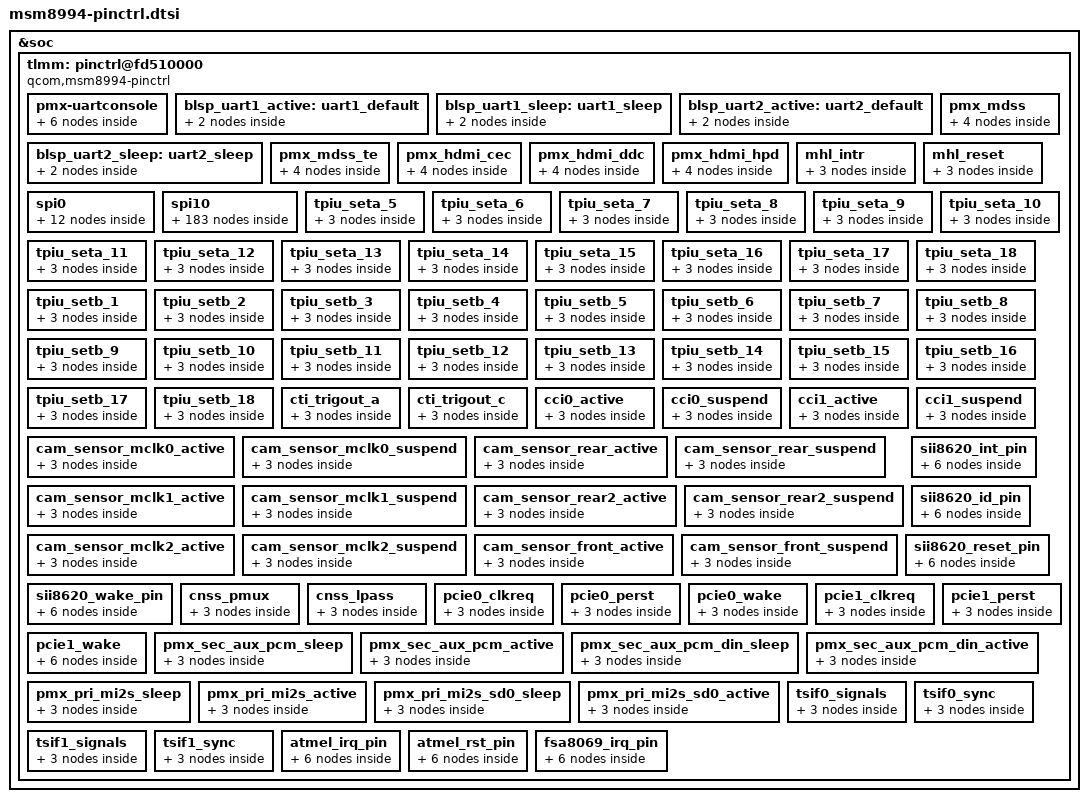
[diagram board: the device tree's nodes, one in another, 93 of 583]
/* Copyright (c) 2013-2015, The Linux Foundation. All rights reserved.
 *
 * This program is free software; you can redistribute it and/or modify
 * it under the terms of the GNU General Public License version 2 and
 * only version 2 as published by the Free Software Foundation.
 *
 * This program is distributed in the hope that it will be useful,
 * but WITHOUT ANY WARRANTY; without even the implied warranty of
 * MERCHANTABILITY or FITNESS FOR A PARTICULAR PURPOSE.  See the
 * GNU General Public License for more details.
 */

&soc {
	tlmm: pinctrl@fd510000 {
		compatible = "qcom,msm8994-pinctrl";
		reg = <0xfd510000 0x4000>;
		interrupts = <0 208 0>;
		gpio-controller;
		#gpio-cells = <2>;
		interrupt-controller;
		#interrupt-cells = <2>;

		pmx-uartconsole {
			uart_console_active: uart_console_active {
				mux {
					pins = "gpio4", "gpio5";
					function = "blsp_uart2";
				};

				config {
					pins = "gpio4", "gpio5";
					drive-strength = <2>;
					bias-disable;
				};
			};

			uart_console_sleep: uart_console_sleep {
				mux {
					pins = "gpio4", "gpio5";
					function = "blsp_uart2";
				};

				config {
					pins = "gpio4", "gpio5";
					drive-strength = <2>;
					bias-pull-down;
				};
			};
		};

		// add by ztemt start
		// add the uart pinctrl for IR-remote control
		blsp_uart1_active: uart1_default {
			mux {
				pins = "gpio0", "gpio1", "gpio2", "gpio3";
				function = "blsp_uart1";
			};

			config {
				pins = "gpio0", "gpio1", "gpio2", "gpio3";
				drive-strength = <16>;
				bias-disable;
			};
		};

		blsp_uart1_sleep: uart1_sleep {
			mux {
				pins = "gpio0", "gpio1";
				function = "gpio";
			};

			config {
				pins = "gpio0", "gpio1";
				drive-strength = <2>;
				bias-pull-down;
				output-low;
			};
		};
		// add by ztemt end

		blsp_uart2_active: uart2_default {
			mux {
				pins = "gpio45", "gpio46", "gpio47", "gpio48";
				function = "blsp_uart8";
			};

			config {
				pins = "gpio45", "gpio46", "gpio47", "gpio48";
				drive-strength = <16>;
				bias-disable;
			};
		};

		blsp_uart2_sleep: uart2_sleep {
			mux {
				pins = "gpio45", "gpio46", "gpio47", "gpio48";
				function = "gpio";
			};

			config {
				pins = "gpio45", "gpio46", "gpio47", "gpio48";
				drive-strength = <2>;
				bias-disable;
			};
		};

		pmx_mdss: pmx_mdss {
			// label = "mdss-pins";
			// qcom,pin-func = <0>;
			mdss_dsi_active: active {
				config {
					drive-strength = <8>; /* 8 mA */
					bias-disable = <0>; /* no pull */
				};
			};
			mdss_dsi_suspend: suspend {
				config {
					drive-strength = <2>; /* 2 mA */
					bias-pull-down; /* pull down */
				};
			};
		};

		pmx_mdss_te: pmx_mdss_te {
			// label = "mdss-te-pins";
			// qcom,pin-func = <1>;
			mdss_te_active: active {
				config {
					drive-strength = <2>; /* 8 mA */
					bias-pull-down = <0>; /* pull down*/
					input-debounce = <0>;
				};
			};
			mdss_te_suspend: suspend {
				config {
					drive-strength = <2>; /* 2 mA */
					bias-pull-down; /* pull down */
					input-debounce = <0>;
				};
			};
		};

		pmx_hdmi_cec: pmx_hdmi_cec {
			// qcom,pin-func = <1>;
			// label = "hdmi-cec-pins";
			mdss_hdmi_cec_active: cec_active {
				config {
					drive-strength = <2>;
					bias-pull-up;
				};
			};
			mdss_hdmi_cec_suspend: cec_suspend {
				config {
					drive-strength = <2>;
					bias-pull-down;
				};
			};
		};

		pmx_hdmi_ddc: pmx_hdmi_ddc {
			// qcom,pin-func = <1>;
			// label = "hdmi-ddc-pins";
			mdss_hdmi_ddc_active: ddc_active {
				config {
					drive-strength = <2>;
					bias-pull-up;
				};
			};
			mdss_hdmi_ddc_suspend: ddc_suspend {
				config {
					drive-strength = <2>;
					bias-disable;
				};
			};
		};

		pmx_hdmi_hpd: pmx_hdmi_hpd {
			// qcom,pin-func = <1>;
			// label = "hdmi-hpd-pin";
			mdss_hdmi_hpd_active: hpd_active {
				config {
					drive-strength = <16>;
					bias-pull-down;
				};
			};
			mdss_hdmi_hpd_suspend: hpd_suspend {
				config {
					drive-strength = <2>;
					bias-pull-down;
				};
			};
		};

		mhl_intr: mhl_intr {
			// qcom,pins = <&gp 57>;
			// qcom,num-grp-pins = <1>;
			// qcom,pin-func = <0>;
			// label = "mhl_intr";

			mhl_intr_active: mhl_intr_active {
				mux {
					pins = "gpio57";
					function = "gpio";
				};

				config {
					pins = "gpio57";
					bias-pull-up;
					input-enable;
				};
			};
		};

		mhl_reset: mhl_reset {
			// qcom,pins = <&gp 58>;
			// qcom,num-grp-pins = <1>;
			// qcom,pin-func = <0>;
			// label = "mhl_reset";

			mhl_reset_active: mhl_reset_active {
				mux {
					pins = "gpio58";
					function = "gpio";
				};

				config {
					pins = "gpio58";
					drive-strength = <2>;
					bias-pull-down;
					output-low;
				};
			};
		};

		spi0 {

			spi_0_active: spi0_active {
				/* active state */
				mux {
					/* MOSI, MISO, CLK */
					pins = "gpio0", "gpio1", "gpio3";
					function = "blsp_spi1";
				};

				config {
					pins = "gpio0", "gpio1", "gpio3";
					drive-strength = <12>; /* 12 MA */
					bias-disable = <0>; /* No PULL */
				};
			};


			spi_0_sleep: spi0_sleep {
				/* suspended state */
				mux {
					/* MOSI, MISO, CLK */
					pins = "gpio0", "gpio1", "gpio3";
					function = "blsp_spi1";
				};

				config {
					pins = "gpio0", "gpio1", "gpio3";
					drive-strength = <2>; /* 2 MA */
					bias-pull-down; /* PULL Down */
				};
			};

			spi_0_cs1_active: cs1_active {
				/* CS */
				mux {
					pins = "gpio8";
					function = "blsp_spi1";
				};

				config {
					pins = "gpio8";
					drive-strength = <2>;
					bias-disable = <0>;
				};
			};

			spi_0_cs1_sleep: cs1_sleep {
				/* CS */
				mux {
					pins = "gpio8";
					function = "blsp_spi1";
				};

				config {
					pins = "gpio8";
					drive-strength = <2>;
					bias-disable = <0>;
				};
			};
		};

		
	/* spi_10 */
		spi10 {
			spi_10_active: spi10_active {

				mux {
					/* MOSI, MISO */
					pins = "gpio53", "gpio54";
					function = "blsp_spi10";
				};

				config {
					pins = "gpio53", "gpio54";
					drive-strength = <2>; /* 2 MA */
					bias-disable = <0>;
				};
			};

			spi_10_sleep: spi10_sleep {
				mux {
					/* MOSI, MISO */
					pins = "gpio53", "gpio54";
					function = "blsp_spi10";
				};

				config {
					pins = "gpio53", "gpio54";
					drive-strength = <2>; /* 2 MA */
					bias-pull-down;
				};
			};

			spi_10_cs10_active: spi_cs10_active {
				/* CS10 , CLK */
				mux {
					/* MOSI, MISO */
					pins = "gpio55", "gpio56";
					function = "blsp_spi10";
				};

				config {
					pins = "gpio55", "gpio56";
					drive-strength = <2>; /* 2 MA */
					bias-disable = <0>;
				};
			};

			spi_10_cs10_sleep: spi_cs10_sleep {
				mux {
					/* MOSI, MISO */
					pins = "gpio55", "gpio56";
					function = "blsp_spi10";
				};

				config {
					pins = "gpio55", "gpio56";
					drive-strength = <2>; /* 2 MA */
					bias-disable = <0>;
				};

		};

	/* spi_12 */
		spi12 {
			spi_12_active: spi12_active {
				mux {
					/* MOSI, MISO */
					pins = "gpio85", "gpio86";
					function = "blsp_spi12";
				};

				config {
					pins = "gpio85", "gpio86";
					drive-strength = <2>; /* 2 MA */
					bias-disable = <0>;
				};
			};
			
			spi_12_sleep: spi12_sleep {
				mux {
					/* MOSI, MISO */
					pins = "gpio85", "gpio86";
					function = "blsp_spi12";
				};

				config {
					pins = "gpio85", "gpio86";
					drive-strength = <2>; /* 2 MA */
					bias-pull-down;
				};
			};

			spi_12_cs_active: cs12_active {
				/* CS12 , CLK */
				mux {
					pins = "gpio87", "gpio88";
					function = "blsp_spi12";
				};

				config {
					pins = "gpio87", "gpio88";
					drive-strength = <8>; /* 2 MA */
					bias-disable = <0>;
				};
			};

			spi_12_cs_sleep: cs12_sleep {
				mux {
					/* MOSI, MISO */
					pins = "gpio87", "gpio88";
					function = "blsp_spi12";
				};

				config {
					pins = "gpio87", "gpio88";
					drive-strength = <2>; /* 2 MA */
					bias-disable = <0>;
				};
			};
		};
		pmx_i2c_1 {
			i2c_1_active: i2c_1_active {
				mux {
					/* SDA, SCL */
					pins = "gpio2", "gpio3";
					function = "blsp_i2c1";
				};

				config {
					pins = "gpio2", "gpio3";
					drive-strength = <2>; /* 2 MA */
					bias-disable;
				};
			};

			i2c_1_sleep: i2c_1_sleep {
				mux {
					/* SDA, SCL */
					pins = "gpio2", "gpio3";
					function = "blsp_i2c1";
				};

				config {
					pins = "gpio2", "gpio3";
					drive-strength = <2>; /* 2 MA */
					bias-disable;
				};
			};
		};

		audio_ext_devices {
			/* default state */
			audio_ext_speakers: audio_ext_speakers {
				mux {
					pins = "gpio96";
					function = "gpio";
				};

				config {
					pins = "gpio96";
					drive-strength = <2>; /* 2 MA */
					bias-pull-up;
				};
			};
		};

		/* SDC pin type */
		sdc: sdc {
			/*
			 * 0-3 for sdc1
			 * 4-6 for sdc2
			 * 7-9 for sdc3
			 */
			qcom,num-pins = <10>;
			/*
			 * Order of pins:
			 * SDC1: CLK -> 0, CMD -> 1, DATA -> 2, RCLK -> 3
			 * SDC2: CLK -> 4, CMD -> 5, DATA -> 6
			 * SDC3: CLK -> 7, CMD -> 8, DATA -> 9
			 */
			#qcom,pin-cells = <1>;
		};

		pmx_sdc1_clk {
			sdc1_clk_on: clk_on {
				config {
					pins = "sdc1_clk";
					bias-disable;		/* NO pull */
					drive-strength = <16>;	/* 16 MA */
				};
			};
			sdc1_clk_off: clk_off {
				config {
					pins = "sdc1_clk";
					bias-disable;		/* NO pull */
					drive-strength = <2>;	/* 2 MA */
				};
			};
		};

		pmx_sdc1_cmd {
			sdc1_cmd_on: cmd_on {
				config {
					pins = "sdc1_cmd";
					bias-pull-up;		/* pull up */
					drive-strength = <8>;	/* 8 MA */
				};
			};
			sdc1_cmd_off: cmd_off {
				config {
					pins = "sdc1_cmd";
					num-grp-pins = <1>;
					bias-pull-up;		/* pull up */
					drive-strength = <2>;	/* 2 MA */
				};
			};
		};

		pmx_sdc1_data {
			sdc1_data_on: data_on {
				config {
					pins = "sdc1_data";
					bias-pull-up;		/* pull up */
					drive-strength = <8>;	/* 8 MA */
				};
			};
			sdc1_data_off: data_off {
				config {
					pins = "sdc1_data";
					bias-pull-up;		/* pull up */
					drive-strength = <2>;	/* 2 MA */
				};
			};
		};

		pmx_sdc1_rclk {
			sdc1_rclk_on: rclk_on {
				config {
					pins = "sdc1_rclk";
					bias-pull-down;		/* pull down */
				};
			};
			sdc1_rclk_off: rclk_off {
				config {
					pins = "sdc1_rclk";
					bias-pull-down;		/* pull down */
				};
			};
		};

		pmx_sdc2_clk {
			sdc2_clk_on: clk_on {
				config {
					pins = "sdc2_clk";
					bias-disable;		/* NO pull */
					drive-strength = <16>;	/* 16 MA */
				};
			};
			sdc2_clk_off: clk_off {
				config {
					pins = "sdc2_clk";
					bias-disable;		/* NO pull */
					drive-strength = <2>;	/* 2 MA */
				};
			};
		};

		pmx_sdc2_cmd {
			sdc2_cmd_on: cmd_on {
				config {
					pins = "sdc2_cmd";
					bias-pull-up;		/* pull up */
					drive-strength = <10>;	/* 10 MA */
				};
			};
			sdc2_cmd_off: cmd_off {
				config {
					pins = "sdc2_cmd";
					bias-pull-up;		/* pull up */
					drive-strength = <2>;	/* 2 MA */
				};
			};
		};

		pmx_sdc2_data {
			sdc2_data_on: data_on {
				config {
					pins = "sdc2_data";
					bias-pull-up;		/* pull up */
					drive-strength = <10>;	/* 10 MA */
				};
			};
			sdc2_data_off: data_off {
				config {
					pins = "sdc2_data";
					bias-pull-up;		/* pull up */
					drive-strength = <2>;	/* 2 MA */
				};
			};
		};

		pmx_sdc3_clk {
			sdc3_clk_on: clk_on {
				config {
					pins = "sdc3_clk";
					bias-disable;		/* NO pull */
					drive-strength = <16>;	/* 16 MA */
				};
			};
			sdc3_clk_off: clk_off {
				config {
					pins = "sdc3_clk";
					bias-disable;		/* NO pull */
					drive-strength = <2>;	/* 2 MA */
				};
			};
		};

		pmx_sdc3_cmd {
			sdc3_cmd_on: cmd_on {
				config {
					pins = "sdc3_cmd";
					bias-pull-up;		/* pull up */
					drive-strength = <10>;	/* 10 MA */
				};
			};
			sdc3_cmd_off: cmd_off {
				config {
					pins = "sdc3_cmd";
					bias-pull-up;		/* pull up */
					drive-strength = <2>;	/* 2 MA */
				};
			};
		};

		pmx_sdc3_data {
			sdc3_data_on: data_on {
				config {
					pins = "sdc3_data";
					bias-pull-up;		/* pull up */
					drive-strength = <10>;	/* 10 MA */
				};
			};
			sdc3_data_off: data_off {
				config {
					pins = "sdc3_data";
					bias-pull-up;		/* pull up */
					drive-strength = <2>;	/* 2 MA */
				};
			};
		};

		pmx_i2c_2 {
			/* active state */
			i2c_2_active: i2c_2_active{
				mux {
					/* CLK, DATA */
					pins = "gpio6", "gpio7";
					function = "blsp_i2c2";
				};

				config {
					pins = "gpio6", "gpio7";
					drive-strength = <2>; /* 2 MA */
					bias-disable; /* No PULL */
				};
			};

			/* suspended state */
			i2c_2_sleep: i2c_2_sleep {
				mux {
					/* CLK, DATA */
					pins = "gpio6", "gpio7";
					function = "blsp_i2c2";
				};

				config {
					pins = "gpio6", "gpio7";
					drive-strength = <2>; /* 2 MA */
					bias-disable; /* No PULL */
				};
			};
		};

		pmx_i2c_11 {
			/* active state */
			i2c_11_active: i2c_11_active{
				mux {
					/* CLK, DATA */
					pins = "gpio83", "gpio84";
					function = "blsp_i2c11";
				};

				config {
					pins = "gpio83", "gpio84";
					drive-strength = <2>; /* 2 MA */
					bias-disable; /* No PULL */
				};
			};

			/* suspended state */
			i2c_11_sleep: i2c_11_sleep {
				mux {
					/* CLK, DATA */
					pins = "gpio83", "gpio84";
					function = "blsp_i2c11";
				};

				config {
					pins = "gpio83", "gpio84";
					drive-strength = <2>; /* 2 MA */
					bias-disable; /* No PULL */
				};
			};
		};

		pmx_fm_int_active {
			// qcom,pins = <&gp 9>;
			// qcom,pin-func = <0>;
			// qcom,num-grp-pins = <1>;
			// label = "pmx_fm_int_active";

			fm_int_active: fm_int_active {
				mux {
					pins = "gpio9";
					function = "gpio";
				};

				config {
					pins = "gpio9";
					drive-strength = <16>;
					bias-pull-up;
				};
			};
		};

		pmx_fm_int_suspend {
			fm_int_suspend: fm_int_suspend {
				mux {
					pins = "gpio9";
					function = "gpio";
				};

				config {
					pins = "gpio9";
					drive-strength = <16>;
					bias-pull-up;
				};
			};
		};

		pmx_fm_status_int_active {
			fm_status_int_active: fm_status_int_active {
				mux {
					pins = "gpio11";
					function = "gpio";
				};

				config {
					pins = "gpio11";
					drive-strength = <16>;
					bias-pull-up;
				};
			};
		};

		pmx_fm_status_int_suspend {
			fm_status_int_suspend: fm_status_int_suspend {
				mux {
					pins = "gpio11";
					function = "gpio";
				};

				config {
					pins = "gpio11";
					drive-strength = <16>;
					bias-pull-up;
				};
			};
		};

		pmx_fm_rst_active {
			fm_rst_active: fm_rst_active {
				mux {
					pins = "gpio62";
					function = "gpio";
				};

				config {
					pins = "gpio62";
					drive-strength = <16>;
					bias-pull-down;
				};
			};
		};

		pmx_fm_rst_suspend {
			fm_rst_suspend: fm_rst_suspend {
				mux {
					pins = "gpio62";
					function = "gpio";
				};

				config {
					pins = "gpio62";
					drive-strength = <16>;
					bias-pull-down;
				};
			};
		};

		pmx_i2c_6 {
			/* active state */
			i2c_6_active: i2c_6_active{
				mux {
					/* SDA, SCL */
					pins = "gpio28", "gpio27";
					function = "blsp_i2c6";
				};

				config {
					pins = "gpio28", "gpio27";
					drive-strength = <2>; /* 2 MA */
					bias-disable; /* No PULL */
				};
			};

			/* suspended state */
			i2c_6_sleep: i2c_6_sleep {
				mux {
					/* CLK, DATA */
					pins = "gpio28", "gpio27";
					function = "blsp_i2c6";
				};

				config {
					pins = "gpio28", "gpio27";
					drive-strength = <2>; /* 2 MA */
					bias-disable; /* No PULL */
				};
			};
		};

		// add by ztemt start
		// add the senor pinctrl
		als_prox_int{
			// qcom,pins = <&gp 40>;
			// qcom,pin-func = <0>;
			// qcom,num-grp-pins = <1>;
			// label = "als_prox_int";

			als_prox_int_active: active {
				mux {
					pins = "gpio40";
					function = "gpio";
				};

				config {
					pins = "gpio40";
					drive-strength = <12>;
					bias-pull-up;
				};
			};

			als_prox_int_suspend: suspend {
				mux {
					pins = "gpio40";
					function = "gpio";
				};

				config {
					pins = "gpio40";
					drive-strength = <6>;
					bias-pull-up;
				};
			};
		};
		// add by ztemt end
/*
		pmx_rd_nfc_int{
			qcom,pins = <&gp 29>;
			qcom,pin-func = <0>;
			qcom,num-grp-pins = <1>;
			label = "pmx_nfc_int";

			nfc_int_active: active {
				drive-strength = <6>;
				bias-pull-up;
			};

			nfc_int_suspend: suspend {
				drive-strength = <6>;
				bias-pull-up;
			};
		};

		pmx_nfc_reset{
			qcom,pins = <&gp 30>;
			qcom,pin-func = <0>;
			qcom,num-grp-pins = <1>;
			label = "pmx_nfc_disable";

			nfc_disable_active: active {
				drive-strength = <6>;
				bias-pull-up;
			};

			nfc_disable_suspend: suspend {
				drive-strength = <6>;
				bias-disable;
			};
		};
*/
		/*add by chengdongsheng for nfc brcm2079x*/
		bcm2079x_int_pin{
			bcm2079x_int_active: active {
				mux {
					pins = "gpio29";
					function = "gpio";
				};

				config {
					pins = "gpio29";
					drive-strength = <6>;
					bias-pull-up;
				};
			};
			
			bcm2079x_int_suspend: suspend {
				mux {
					pins = "gpio29";
					function = "gpio";
				};

				config {
					pins = "gpio29";
					drive-strength = <6>;
					bias-pull-up;
				};
			};
		};

		bcm2079x_en_pin{
			bcm2079x_en_active: active {
				mux {
					pins = "gpio26";
					function = "gpio";
				};

				config {
					pins = "gpio26";
					drive-strength = <6>;
					bias-pull-up;
				};
			};
			bcm2079x_en_suspend: suspend {
				mux {
					pins = "gpio26";
					function = "gpio";
				};

				config {
					pins = "gpio26";
					drive-strength = <6>;
					bias-disable;
				};
			};

		bcm2079x_ctl_pin{
			bcm2079x_ctl_active: active {
				mux {
					pins = "gpio30";
					function = "gpio";
				};

				config {
					pins = "gpio30";
					drive-strength = <6>;
					bias-pull-up;
				};
			};
			bcm2079x_ctl_suspend: suspend {
				mux {
					pins = "gpio30";
					function = "gpio";
				};

				config {
					pins = "gpio30";
					drive-strength = <6>;
					bias-disable;
				};
			};
		};
	};
		
		pmx_ts {
			// qcom,pins = <&gp 60>, <&gp 61>;
			// qcom,pin-func = <0>;
			// qcom,num-grp-pins = <2>;
			// label = "pmx_ts";

			ts_active: ts_active {
				mux {
					pins = "gpio60", "gpio61";
					function = "gpio";
				};

				config {
					pins = "gpio60", "gpio61";
					drive-strength = <16>;
					bias-pull-up;
				};
			};

			ts_suspend: ts_suspend {
				mux {
					pins = "gpio60", "gpio61";
					function = "gpio";
				};

				config {
					pins = "gpio60", "gpio61";
					drive-strength = <16>;
					bias-disable;
				};
			};
		};

		/* CoreSight */
		tpiu_seta_1 {
			seta_1: seta {
				mux {
					pins = "gpio27";
					function = "qdss_tracectl_a";
				};

				config {
					pins = "gpio27";
					drive-strength = <16>;
					bias-disable;
				};
			};
		};

		tpiu_seta_2 {
			seta_2: seta {
				mux {
					pins = "gpio28";
					function = "qdss_traceclk_a";
				};

				config {
					pins = "gpio28";
					drive-strength = <16>;
					bias-disable;
				};
			};
		};

		tpiu_seta_3 {
			seta_3: seta {
				mux {
					pins = "gpio53";
					function = "qdss_tracedata_a";
				};

				config {
					pins = "gpio53";
					drive-strength = <16>;
					bias-disable;
				};
			};
		};

		tpiu_seta_4 {
			seta_4: seta {
				mux {
					pins = "gpio54";
					function = "qdss_tracedata_a";
				};

				config {
					pins = "gpio54";
					drive-strength = <16>;
					bias-disable;
				};
			};
			};
		};

		tpiu_seta_5 {
			seta_5: seta {
				mux {
					pins = "gpio63";
					function = "qdss_tracedata_a";
				};

				config {
					pins = "gpio63";
					drive-strength = <16>;
					bias-disable;
				};
			};
		};

		tpiu_seta_6 {
			seta_6: seta {
				mux {
					pins = "gpio64";
					function = "qdss_tracedata_a";
				};

				config {
					pins = "gpio64";
					drive-strength = <16>;
					bias-disable;
				};
			};
		};

		tpiu_seta_7 {
			seta_7: seta {
				mux {
					pins = "gpio65";
					function = "qdss_tracedata_a";
				};

				config {
					pins = "gpio65";
					drive-strength = <16>;
					bias-disable;
				};
			};
		};

		tpiu_seta_8 {
			seta_8: seta {
				mux {
					pins = "gpio66";
					function = "qdss_tracedata_a";
				};

				config {
					pins = "gpio66";
					drive-strength = <16>;
					bias-disable;
				};
			};
		};

		tpiu_seta_9 {
			seta_9: seta {
				mux {
					pins = "gpio67";
					function = "qdss_tracedata_a";
				};

				config {
					pins = "gpio67";
					drive-strength = <16>;
					bias-disable;
				};
			};
		};

		tpiu_seta_10 {
			seta_10: seta {
				mux {
					pins = "gpio74";
					function = "qdss_tracedata_a";
				};

				config {
					pins = "gpio74";
					drive-strength = <16>;
					bias-disable;
				};
			};
		};

		tpiu_seta_11 {
			seta_11: seta {
				mux {
					pins = "gpio75";
					function = "qdss_tracedata_a";
				};

				config {
					pins = "gpio75";
					drive-strength = <16>;
					bias-disable;
				};
			};
		};

		tpiu_seta_12 {
			seta_12: seta {
				mux {
					pins = "gpio76";
					function = "qdss_tracedata_a";
				};

				config {
					pins = "gpio76";
					drive-strength = <16>;
					bias-disable;
				};			};
		};

		tpiu_seta_13 {
			seta_13: seta {
				mux {
					pins = "gpio77";
					function = "qdss_tracedata_a";
				};

				config {
					pins = "gpio77";
					drive-strength = <16>;
					bias-disable;
				};
			};
		};

		tpiu_seta_14 {
			seta_14: seta {
				mux {
					pins = "gpio85";
					function = "qdss_tracedata_a";
				};

				config {
					pins = "gpio85";
					drive-strength = <16>;
					bias-disable;
				};
			};
		};

		tpiu_seta_15 {
			seta_15: seta {
				mux {
					pins = "gpio86";
					function = "qdss_tracedata_a";
				};

				config {
					pins = "gpio86";
					drive-strength = <16>;
					bias-disable;
				};
			};
		};

		tpiu_seta_16 {
			seta_16: seta {
				mux {
					pins = "gpio87";
					function = "qdss_tracedata_a";
				};

				config {
					pins = "gpio87";
					drive-strength = <16>;
					bias-disable;
				};
			};
		};

		tpiu_seta_17 {
			seta_17: seta {
				mux {
					pins = "gpio89";
					function = "qdss_tracedata_a";
				};

				config {
					pins = "gpio89";
					drive-strength = <16>;
					bias-disable;
				};
			};
		};

		tpiu_seta_18 {
			seta_18: seta {
				mux {
					pins = "gpio90";
					function = "qdss_tracedata_a";
				};

				config {
					pins = "gpio90";
					drive-strength = <16>;
					bias-disable;
				};
			};
		};

		tpiu_setb_1 {
			setb_1: setb {
				mux {
					pins = "gpio13";
					function = "qdss_tracedata_b";
				};

				config {
					pins = "gpio13";
					drive-strength = <16>;
					bias-disable;
				};
			};
		};

		tpiu_setb_2 {
			setb_2: setb {
				mux {
					pins = "gpio14";
					function = "qdss_tracedata_b";
				};

				config {
					pins = "gpio14";
					drive-strength = <16>;
					bias-disable;
				};
			};
		};

		tpiu_setb_3 {
			setb_3: setb {
				mux {
					pins = "gpio15";
					function = "qdss_tracedata_b";
				};

				config {
					pins = "gpio15";
					drive-strength = <16>;
					bias-disable;
				};
			};
		};

		tpiu_setb_4 {
			setb_4: setb {
				mux {
					pins = "gpio16";
					function = "qdss_tracedata_b";
				};

				config {
					pins = "gpio16";
					drive-strength = <16>;
					bias-disable;
				};
			};
		};

		tpiu_setb_5 {
			setb_5: setb {
				mux {
					pins = "gpio17";
					function = "qdss_tracedata_b";
				};

				config {
					pins = "gpio17";
					drive-strength = <16>;
					bias-disable;
				};
			};
		};

		tpiu_setb_6 {
			setb_6: setb {
				mux {
					pins = "gpio18";
					function = "qdss_tracedata_b";
				};

				config {
					pins = "gpio18";
					drive-strength = <16>;
					bias-disable;
				};
			};
		};

		tpiu_setb_7 {
			setb_7: setb {
				mux {
					pins = "gpio19";
					function = "qdss_tracedata_b";
				};

				config {
					pins = "gpio19";
					drive-strength = <16>;
					bias-disable;
				};
			};
		};

		tpiu_setb_8 {
			setb_8: setb {
				mux {
					pins = "gpio21";
					function = "qdss_tracedata_b";
				};

				config {
					pins = "gpio21";
					drive-strength = <16>;
					bias-disable;
				};
			};
		};

		tpiu_setb_9 {
			setb_9: setb {
				mux {
					pins = "gpio22";
					function = "qdss_tracedata_b";
				};

				config {
					pins = "gpio22";
					drive-strength = <16>;
					bias-disable;
				};
			};
		};

		tpiu_setb_10 {
			setb_10: setb {
				mux {
					pins = "gpio23";
					function = "qdss_tracedata_b";
				};

				config {
					pins = "gpio23";
					drive-strength = <16>;
					bias-disable;
				};
			};
		};

		tpiu_setb_11 {
			setb_11: setb {
				mux {
					pins = "gpio25";
					function = "qdss_tracedata_b";
				};

				config {
					pins = "gpio25";
					drive-strength = <16>;
					bias-disable;
				};
			};
		};

		tpiu_setb_12 {
			setb_12: setb {
				mux {
					pins = "gpio26";
					function = "qdss_tracedata_b";
				};

				config {
					pins = "gpio26";
					drive-strength = <16>;
					bias-disable;
				};
			};
		};

		tpiu_setb_13 {
			setb_13: setb {
				mux {
					pins = "gpio57";
					function = "qdss_tracedata_b";
				};

				config {
					pins = "gpio57";
					drive-strength = <16>;
					bias-disable;
				};
			};
		};

		tpiu_setb_14 {
			setb_14: setb {
				mux {
					pins = "gpio58";
					function = "qdss_tracedata_b";
				};

				config {
					pins = "gpio58";
					drive-strength = <16>;
					bias-disable;
				};
			};
		};

		tpiu_setb_15 {
			setb_15: setb {
				mux {
					pins = "gpio91";
					function = "qdss_traceclk_b";
				};

				config {
					pins = "gpio91";
					drive-strength = <16>;
					bias-disable;
				};
			};
		};

		tpiu_setb_16 {
			setb_16: setb {
				mux {
					pins = "gpio92";
					function = "qdss_tracedata_b";
				};

				config {
					pins = "gpio92";
					drive-strength = <16>;
					bias-disable;
				};
			};
		};

		tpiu_setb_17 {
			setb_17: setb {
				mux {
					pins = "gpio93";
					function = "qdss_tracedata_b";
				};

				config {
					pins = "gpio93";
					drive-strength = <16>;
					bias-disable;
				};
			};
		};

		tpiu_setb_18 {
			setb_18: setb {
				mux {
					pins = "gpio94";
					function = "qdss_tracectl_b";
				};

				config {
					pins = "gpio94";
					drive-strength = <16>;
					bias-disable;
				};
			};
		};
		cti_trigout_a {
			trigout_a: trigout_a {
				mux {
					pins = "gpio56";
					function = "qdss_cti_trig_out_a";
				};
				config {
					pins = "gpio56";
					drive-strength = <16>;
					bias-disable;
				};
			};
		};

		cti_trigout_c {
			trigout_c: trigout_c {
				mux {
					pins = "gpio41";
					function = "qdss_cti_trig_out_c";
				};

				config {
					pins = "gpio41";
					drive-strength = <16>;
					bias-disable;
				};
			};
		};

		cci0_active {
			/* CLK, DATA */
			// qcom,pins = <&gp 17>, <&gp 18>;
			// qcom,num-grp-pins = <2>;
			// qcom,pin-func = <1>;
			// label = "cci0-active";
			/* active state */
			cci0_active: cci0_active {
				mux {
					/* CLK, DATA */
					pins = "gpio17","gpio18"; // Only 2
					function = "cci_i2c0";
				};

				config {
					pins = "gpio17","gpio18";
					drive-strength = <2>; /* 2 MA */
					bias-disable; /* No PULL */
				};
			};
		};

		cci0_suspend {
			/*suspended state */
			cci0_suspend: cci0_suspend {
				mux {
					/* CLK, DATA */
					pins = "gpio17","gpio18";
					function = "cci_i2c0";
				};

				config {
					pins = "gpio17","gpio18";
					drive-strength = <2>; /* 2 MA */
					bias-disable; /* No PULL */
				};
			};
		};

		cci1_active {
			/* CLK, DATA */
			// qcom,pins = <&gp 19>, <&gp 20>;
			// qcom,num-grp-pins = <2>;
			// qcom,pin-func = <1>;
			// label = "cci1-active";
			/* active state */
			cci1_active: cci1_active {
				mux {
					/* CLK, DATA */
					pins = "gpio19","gpio20";
					function = "cci_i2c1";
				};

				config {
					pins = "gpio19","gpio20";
					drive-strength = <2>; /* 2 MA */
					bias-disable; /* No PULL */
				};
			};
		};

		cci1_suspend {
			/* CLK, DATA */
			// qcom,pins = <&gp 19>, <&gp 20>;
			// qcom,num-grp-pins = <2>;
			// qcom,pin-func = <0>;
			// label = "cci1-suspend";
			/*suspended state */
			cci1_suspend: cci1_suspend {
				mux {
					/* CLK, DATA */
					pins = "gpio19","gpio20";
					function = "cci_i2c1";
				};

				config {
					pins = "gpio19","gpio20";
					drive-strength = <2>; /* 2 MA */
					bias-disable; /* No PULL */
				};
			};
		};

		cam_sensor_mclk0_active {
			/* MCLK0 */
			// qcom,pins = <&gp 13>;
			// qcom,num-grp-pins = <1>;
			// qcom,pin-func = <1>;
			// label = "cam_sensor_mclk0_active";
			/* active state */
			cam_sensor_mclk0_active: cam_sensor_mclk0_active {
			/* MCLK0 */
				mux {
					/* CLK, DATA */
					pins = "gpio13";
					function = "cam_mclk0";
				};

				config {
					pins = "gpio13";
					drive-strength = <2>; /* 2 MA */
					bias-disable; /* No PULL */
				};
			};
		};

		cam_sensor_mclk0_suspend {
			/* MCLK0 */
			// qcom,pins = <&gp 13>;
			// qcom,num-grp-pins = <1>;
			// label = "cam_sensor_mclk0_suspend";
			/*suspended state */
			cam_sensor_mclk0_suspend: cam_sensor_mclk0_suspend {
				/* MCLK0 */
				mux {
					/* CLK, DATA */
					pins = "gpio13";
					function = "cam_mclk0";
				};

				config {
					pins = "gpio13";
					drive-strength = <2>; /* 2 MA */
					bias-pull-down; /* PULL DOWN */
				};
			};
		};

		cam_sensor_rear_active {
			/* RESET, STANDBY */
                        // ZTEMT: fuyipeng modify for camera -----start
			// qcom,pins = <&gp 92>, <&gp 91>, <&gp 21>;
			// qcom,num-grp-pins = <3>;
            //             // ZTEMT: fuyipeng modify for camera -----end
			// label = "cam_sensor_rear_active";
			/* active state */
			cam_sensor_rear_active: cam_sensor_rear_active {
			/* RESET, STANDBY */
				mux {
					pins = "gpio92","gpio91","gpio21";
					function = "gpio";
				};

				config {
					pins = "gpio92","gpio91","gpio21";
					drive-strength = <2>; /* 2 MA */
					bias-disable; /* No PULL */
				};
			};
		};

		cam_sensor_rear_suspend {
			/* RESET, STANDBY */
                        // ZTEMT: fuyipeng modify for camera -----start
			// qcom,pins = <&gp 92>, <&gp 91>, <&gp 21>;
			// qcom,num-grp-pins = <3>;
            //             // ZTEMT: fuyipeng modify for camera -----end
			// label = "cam_sensor_rear_suspend";
			/*suspended state */
			cam_sensor_rear_suspend: cam_sensor_rear_suspend {
			/* RESET, STANDBY */
				mux {
					pins = "gpio92","gpio91","gpio21";
					function = "gpio";
				};

				config {
					pins = "gpio92","gpio91","gpio21";
					drive-strength = <2>; /* 2 MA */
					bias-disable; /* No PULL */
				};
			};
		};

		cam_sensor_mclk1_active {
			/* MCLK1 */
			// qcom,pins = <&gp 14>;
			// qcom,num-grp-pins = <1>;
			// qcom,pin-func = <1>;
			// label = "cam_sensor_mclk1_active";
			/* active state */
			cam_sensor_mclk1_active: cam_sensor_mclk1_active {
				/* MCLK1 */
				mux {
					/* CLK, DATA */
					pins = "gpio14";
					function = "cam_mclk1";
				};

				config {
					pins = "gpio14";
					drive-strength = <2>; /* 2 MA */
					bias-disable; /* No PULL */
				};
			};
		};

		cam_sensor_mclk1_suspend {
			/* MCLK1 */
			// qcom,pins = <&gp 14>;
			// qcom,num-grp-pins = <1>;
			// label = "cam_sensor_mclk1_suspend";
			/* suspend state */
			cam_sensor_mclk1_suspend: cam_sensor_mclk1_suspend {
				/* MCLK1 */
				mux {
					/* CLK, DATA */
					pins = "gpio14";
					function = "cam_mclk1";
				};

				config {
					pins = "gpio14";
					drive-strength = <2>; /* 2 MA */
					bias-pull-down; /* PULL DOWN */
				};
			};
		};

		cam_sensor_rear2_active {
			/* RESET, STANDBY */
			// qcom,pins = <&gp 94>, <&gp 93>;
			// qcom,num-grp-pins = <2>;
			// label = "cam_sensor_rear2_active";
			/* active state */
			cam_sensor_rear2_active: cam_sensor_rear2_active {
				/* RESET, STANDBY */
				mux {
					pins = "gpio94","gpio93";
					function = "gpio";
				};

				config {
					pins = "gpio94","gpio93";
					drive-strength = <2>; /* 2 MA */
					bias-disable; /* No PULL */
				};
			};
		};

		cam_sensor_rear2_suspend {
			/* RESET, STANDBY */
			// qcom,pins = <&gp 94>, <&gp 93>;
			// qcom,num-grp-pins = <2>;
			// label = "cam_sensor_rear2_suspend";
			/*suspended state */
			cam_sensor_rear2_suspend: cam_sensor_rear2_suspend {
				/* RESET, STANDBY */
				mux {
					pins = "gpio94","gpio93";
					function = "gpio";
				};

				config {
					pins = "gpio94","gpio93";
					drive-strength = <2>; /* 2 MA */
					bias-disable; /* No PULL */
				};
			};
		};

		cam_sensor_mclk2_active {
			/* MCLK2 */
			// qcom,pins = <&gp 15>;
			// qcom,num-grp-pins = <1>;
			// qcom,pin-func = <1>;
			// label = "cam_sensor_mclk2_active";
			/* active state */
			cam_sensor_mclk2_active: cam_sensor_mclk2_active {
				/* MCLK2 */
				mux {
					/* CLK, DATA */
					pins = "gpio15";
					function = "cam_mclk2";
				};

				config {
					pins = "gpio15";
					drive-strength = <2>; /* 2 MA */
					bias-disable; /* No PULL */
				};
			};
		};

		cam_sensor_mclk2_suspend {
			/* MCLK2 */
			// qcom,pins = <&gp 15>;
			// qcom,num-grp-pins = <1>;
			// label = "cam_sensor_mclk2_suspend";
			/* suspend state */
			cam_sensor_mclk2_suspend: cam_sensor_mclk2_suspend {
				/* MCLK2 */
				mux {
					/* CLK, DATA */
					pins = "gpio15";
					function = "cam_mclk2";
				};

				config {
					pins = "gpio15";
					drive-strength = <2>; /* 2 MA */
					bias-pull-down; /* PULL DOWN */
				};
			};
		};

		cam_sensor_front_active {
			// /* RESET, STANDBY */
            //             // ZTEMT: fuyipeng modify for camera -----start
			// qcom,pins = <&gp 104>, <&gp 105>,<&gp 25>;
			// qcom,num-grp-pins = <3>;
            //             // ZTEMT: fuyipeng modify for camera -----end
			// label = "cam_sensor_front_active";
			/* active state */
			cam_sensor_front_active: cam_sensor_front_active {
				/* RESET, STANDBY */
				mux {
					pins = "gpio104","gpio105","gpio25";
					function = "gpio";
				};

				config {
					pins = "gpio104","gpio105","gpio25";
					drive-strength = <2>; /* 2 MA */
					bias-disable; /* No PULL */
				};
			};
		};

		cam_sensor_front_suspend {
			/* RESET, STANDBY */
                        // ZTEMT: fuyipeng modify for camera -----start
			// qcom,pins = <&gp 104>, <&gp 105>,<&gp 25>;
			// qcom,num-grp-pins = <3>;
            //             // ZTEMT: fuyipeng modify for camera -----end
			// label = "cam_sensor_front_suspend";
			/*suspended state */
			cam_sensor_front_suspend: cam_sensor_front_suspend {
				/* RESET, STANDBY */
				mux {
					pins = "gpio104","gpio105","gpio25";
					function = "gpio";
				};

				config {
					pins = "gpio104","gpio105","gpio25";
					drive-strength = <2>; /* 2 MA */
					bias-disable; /* No PULL */
				};
			};
		};

		sii8620_int_pin{
			// qcom,pins = <&gp 64>;  
			// qcom,num-grp-pins = <1>;
			// qcom,pin-func = <0>;
			// label = "sii8620_int_pin";
			
			sii8620_int_active: sii8620_int_active {
				mux {
					pins = "gpio64";
					function = "gpio";
				};

				config {
					pins = "gpio64";
					drive-strength = <10>;
					bias-pull-up;
				};
			};
			sii8620_int_suspend: sii8620_int_suspend {
				mux {
					pins = "gpio64";
					function = "gpio";
				};

				config {
					pins = "gpio64";
					drive-strength = <2>;
					bias-pull-up;
				};
			};	
		};
	
		sii8620_id_pin{
			// qcom,pins = <&gp 16>;  
			// qcom,num-grp-pins = <1>;
			// qcom,pin-func = <0>;
			// label = "sii8620_id_pin";
			
			sii8620_id_active: sii8620_id_active {
				mux {
					pins = "gpio16";
					function = "gpio";
				};

				config {
					pins = "gpio16";
					drive-strength = <10>;
					bias-pull-up;
				};
			};
			sii8620_id_suspend: sii8620_id_suspend {
				mux {
					pins = "gpio16";
					function = "gpio";
				};

				config {
					pins = "gpio16";
					drive-strength = <2>;
					bias-pull-up;
				};
			};	
		};

		sii8620_reset_pin{
			// qcom,pins = <&gp 58>;  
			// qcom,num-grp-pins = <1>;
			// qcom,pin-func = <0>;
			// label = "sii8620_reset_pin";
			
			sii8620_reset_active: sii8620_reset_active {
				mux {
					pins = "gpio58";
					function = "gpio";
				};

				config {
					pins = "gpio58";
					drive-strength = <10>;
					bias-pull-up;
				};
			};
			sii8620_reset_suspend: sii8620_reset_suspend {
				mux {
					pins = "gpio58";
					function = "gpio";
				};

				config {
					pins = "gpio58";
					drive-strength = <2>;
					bias-pull-up;
				};
			};	
		};
	
		sii8620_wake_pin{
			// qcom,pins = <&gp 12>;  
			// qcom,num-grp-pins = <1>;
			// qcom,pin-func = <0>;
			// label = "sii8620_wake_pin";
			
			sii8620_wake_active: sii8620_wake_active {
				mux {
					pins = "gpio12";
					function = "gpio";
				};

				config {
					pins = "gpio12";
					drive-strength = <10>;
					bias-pull-up;
				};
			};
			sii8620_wake_suspend: sii8620_wake_suspend {
				mux {
					pins = "gpio12";
					function = "gpio";
				};

				config {
					pins = "gpio113";
					drive-strength = <2>;
					bias-pull-up;
				};
			};	
		};

		cnss_pmux: cnss_pmux {
			// qcom,pins = <&gp 113>;
			// qcom,num-grp-pins = <1>;
			// qcom,pin-func = <0>;
			// label = "cnss_pins";
			cnss_default: default {
				mux {
					pins = "gpio113";
					function = "gpio";
				};

				config {
					pins = "gpio113";
					drive-strength = <16>;
					bias-pull-down;
				};
			};
		};

		cnss_lpass: cnss_lpass {
			// qcom,pins = <&gp 112>;
			// qcom,num-grp-pins = <1>;
			// qcom,pin-func = <0>;
			// label = "cnss-lpass";
			/* default state */
			cnss_lpass_default: cnss_lpass_default {
				mux {
					pins = "gpio112";
					function = "gpio";
				};

				config {
					pins = "gpio112";
					drive-strength = <16>;
					bias-pull-down;
				};
			};
		};

		pcie0_clkreq {
			// qcom,pins = <&gp 54>;
			// qcom,num-grp-pins = <1>;
			// qcom,pin-func = <2>;
			// label = "pcie0-clkreq";
			/* default state */
			pcie0_clkreq_default: pcie0_clkreq_default {
				mux {
					pins = "gpio54";
					function = "pci_e0";
				};

				config {
					pins = "gpio54";
				drive-strength = <2>;
				bias-pull-up;
				};
			};
		};

		pcie0_perst {
			// qcom,pins = <&gp 53>;
			// qcom,num-grp-pins = <1>;
			// label = "pcie0-perst";
			/* default state */
			pcie0_perst_default: pcie0_perst_default {
				mux {
					pins = "gpio53";
					function = "gpio";
				};

				config {
					pins = "gpio53";
					drive-strength = <2>;
					bias-pull-down;
				};
			};
		};

		pcie0_wake {
			// qcom,pins = <&gp 55>;
			// qcom,num-grp-pins = <1>;
			// label = "pcie0-wake";
			/* default state */
			pcie0_wake_default: pcie0_wake_default {
				mux {
					pins = "gpio55";
					function = "gpio";
				};

				config {
					pins = "gpio55";
					drive-strength = <2>;
					bias-pull-down;
				};
			};
		};

		pcie1_clkreq {
			// qcom,pins = <&gp 36>;
			// qcom,num-grp-pins = <1>;
			// qcom,pin-func = <2>;
			// label = "pcie1-clkreq";
			/* default state */
			pcie1_clkreq_default: pcie1_clkreq_default {
				mux {
					pins = "gpio36";
					function = "pci_e1";
				};

				config {
					pins = "gpio36";
					drive-strength = <2>;
					bias-pull-up;
				};
			};
		};

		pcie1_perst {
			// qcom,pins = <&gp 35>;
			// qcom,num-grp-pins = <1>;
			// label = "pcie1-perst";
			/* default state */
			pcie1_perst_default: pcie1_perst_default {
				mux {
					pins = "gpio35";
					function = "gpio";
				};

				config {
					pins = "gpio35";
					drive-strength = <2>;
					bias-pull-down;
				};
			};
		};

		pcie1_wake {
			// qcom,pins = <&gp 37>;
			// qcom,num-grp-pins = <1>;
			// label = "pcie1-wake";
			/* default state */
			pcie1_wake_default: pcie1_wake_default {
				mux {
					pins = "gpio37";
					function = "gpio";
				};

				config {
					pins = "gpio37";
					drive-strength = <2>;
					bias-pull-down;
				};
			};

			pcie1_wake_sleep: pcie1_wake_sleep {
				mux {
					pins = "gpio37";
					function = "gpio";
				};

				config {
					pins = "gpio37";
					drive-strength = <2>;
					bias-disable;
				};
			};
		};

		pmx_sec_aux_pcm_sleep {
			// qcom,pins = <&gp 79>, <&gp 80>, <&gp 82>;
			// qcom,num-grp-pins = <3>;
			// qcom,pin-func = <0>;
			// label = "pmx_sec_aux_pcm_sleep";
			sec_aux_pcm_sleep: sec_aux_pcm_sleep {
				mux {
					pins = "gpio79", "gpio80", "gpio82";
					function = "sec_mi2s";
				};

				config {
					pins = "gpio79", "gpio80", "gpio82";
					drive-strength = <2>;	/* 2 mA */
					bias-pull-down;		/* PULL DOWN */
					input-enable;
				};
			};
		};

		pmx_sec_aux_pcm_active {
			// qcom,pins = <&gp 79>, <&gp 80>, <&gp 82>;
			// qcom,num-grp-pins = <3>;
			// qcom,pin-func = <1>;
			// label = "pmx_sec_aux_pcm_active";
			sec_aux_pcm_active: sec_aux_pcm_active {
				mux {
					pins = "gpio79", "gpio80", "gpio82";
					function = "sec_mi2s";
				};

				config {
					pins = "gpio79", "gpio80", "gpio82";
					drive-strength = <8>;	/* 8 mA */
					bias-disable;		/* NO PULL */
					output-high;
				};
			};
		};

		pmx_sec_aux_pcm_din_sleep {
			// qcom,pins = <&gp 81>;
			// qcom,num-grp-pins = <1>;
			// qcom,pin-func = <0>;
			// label = "pmx_sec_aux_pcm_din_sleep";
			sec_aux_pcm_din_sleep: sec_aux_pcm_din_sleep {
				mux {
					pins = "gpio81";
					function = "sec_mi2s";
				};

				config {
					pins = "gpio81";
					drive-strength = <2>;	/* 2 mA */
					bias-pull-down;		/* PULL DOWN */
					input-enable;
				};
			};
		};

		pmx_sec_aux_pcm_din_active {
			// qcom,pins = <&gp 81>;
			// qcom,num-grp-pins = <1>;
			// qcom,pin-func = <1>;
			// label = "pmx_sec_aux_pcm_din_active";
			sec_aux_pcm_din_active: sec_aux_pcm_din_active {
				mux {
					pins = "gpio81";
					function = "sec_mi2s";
				};

				config {
					pins = "gpio81";
					drive-strength = <8>;	/* 8 mA */
					bias-disable;		/* NO PULL */
				};
			};
		};

		pmx_pri_mi2s_sleep {
			// qcom,pins = <&gp 65>, <&gp 66>;
			// qcom,num-grp-pins = <2>;
			// qcom,pin-func = <0>;
			// label = "pri_mi2s_sleep";
			pri_mi2s_sleep: pri_mi2s_sleep {
				mux {
					pins = "gpio65", "gpio66";
					function = "pri_mi2s";
				};

				config {
					pins = "gpio65", "gpio66";
					drive-strength = <2>;	/* 2 mA */
					bias-pull-down;		/* PULL DOWN */
					input-enable;
				};
			};
		};

		pmx_pri_mi2s_active {
			// qcom,pins = <&gp 65>, <&gp 66>;
			// qcom,num-grp-pins = <2>;
			// qcom,pin-func = <1>;
			// label = "pri_mi2s_active";
			pri_mi2s_active: pri_mi2s_active {
				mux {
					pins = "gpio65", "gpio66";
					function = "pri_mi2s";
				};

				config {
					pins = "gpio65", "gpio66";
					drive-strength = <2>;	/* 2 mA */
					bias-disable;		/* NO PULL */
					output-high;
				};
			};
		};

		pmx_pri_mi2s_sd0_sleep {
			// qcom,pins = <&gp 67>;
			// qcom,num-grp-pins = <1>;
			// qcom,pin-func = <0>;
			// label = "pri_mi2s_sd0_sleep";
			pri_mi2s_sd0_sleep: pri_mi2s_sd0_sleep {
				mux {
					pins = "gpio67";
					function = "pri_mi2s";
				};

				config {
					pins = "gpio67";
					drive-strength = <2>;	/* 2 mA */
					bias-pull-down;		/* PULL DOWN */
					input-enable;
				};
			};
		};

		pmx_pri_mi2s_sd0_active {
			// qcom,pins = <&gp 67>;
			// qcom,num-grp-pins = <1>;
			// qcom,pin-func = <1>;
			// label = "pri_mi2s_sd0_active";
			pri_mi2s_sd0_active: pri_mi2s_sd0_active {
				mux {
					pins = "gpio67";
					function = "pri_mi2s";
				};

				config {
					pins = "gpio67";
					drive-strength = <2>;	/* 2 mA */
					bias-disable;		/* NO PULL */
				};
			};
		};

		tsif0_signals {
			// qcom,pins = <&gp 89>,	/* TSIF0 CLK */
			// 	<&gp 90>,	/* TSIF0 Enable */
			// 	<&gp 91>;	/* TSIF0 DATA */
			// qcom,num-grp-pins = <3>;
			// qcom,pin-func = <1>;
			// label = "tsif0-signals";
			tsif0_signals_active: tsif0_signals_active {
				mux {
					pins = "gpio89", "gpio90", "gpio91";
					function = "tsif1";
				};

				config {
					pins = "gpio89", "gpio90", "gpio91";
					drive_strength = <2>;	/* 2 mA */
					bias-pull-down;		/* pull down */
				};
			};
		};

		/* sync signal is only used if configured to mode-2 */
		tsif0_sync {
			// qcom,pins = <&gp 110>;	/* TSIF0 SYNC */
			// qcom,num-grp-pins = <1>;
			// qcom,pin-func = <1>;
			// label = "tsif0-sync";
			tsif0_sync_active: tsif0_sync_active {
				mux {
					pins = "gpio110";
					function = "tsif1";
				};

				config {
					pins = "gpio110";
					drive_strength = <2>;	/* 2 mA */
					bias-pull-down;		/* pull down */
				};
			};
		};

		tsif1_signals {
			// qcom,pins = <&gp 93>,	/* TSIF1 CLK */
			// 	<&gp 94>,	/* TSIF1 Enable */
			// 	<&gp 95>;	/* TSIF1 DATA */
			// qcom,num-grp-pins = <3>;
			// qcom,pin-func = <1>;
			// label = "tsif1-signals";
			tsif1_signals_active: tsif1_signals_active {
				mux {
					pins = "gpio93", "gpio94", "gpio95";
					function = "tsif2";
				};

				config {
					pins = "gpio93", "gpio94", "gpio95";
					drive_strength = <2>;	/* 2 mA */
					bias-pull-down;		/* pull down */
				};
			};
		};

		/* sync signal is only used if configured to mode-2 */
		tsif1_sync {
			// qcom,pins = <&gp 96>;	/* TSIF1 SYNC */
			// qcom,num-grp-pins = <1>;
			// qcom,pin-func = <1>;
			// label = "tsif1-sync";
			tsif1_sync_active: tsif1_sync_active {
				mux {
					pins = "gpio96";
					function = "tsif2";
				};

				config {
					pins = "gpio96";
					drive_strength = <2>;	/* 2 mA */
					bias-pull-down;		/* pull down */
				};
			};
		};
		
		atmel_irq_pin {
			// qcom,pins = <&gp 61>;
			// qcom,num-grp-pins = <1>;
			// qcom,pin-func = <0>;
			// label = "atmel_irt_pin";

			atmel_irq_active: atmel_irq_active {
				mux {
					pins = "gpio61";
					function = "gpio";
				};

				config {
					pins = "gpio61";
					drive-strength = <10>;
					bias-pull-up;
				};
			};

			atmel_irq_suspend: atmel_irq_suspend {
				mux {
					pins = "gpio61";
					function = "gpio";
				};

				config {
					pins = "gpio61";
					drive-strength = <2>;
					bias-pull-up;
				};
			};
		};
		atmel_rst_pin {
			// qcom,pins = <&gp 60>;
			// qcom,num-grp-pins = <1>;
			// qcom,pin-func = <0>;
			// label = "atmel_rst_pin";

			atmel_rst_active: atmel_rst_active {
				mux {
					pins = "gpio60";
					function = "gpio";
				};

				config {
					pins = "gpio60";
					drive-strength = <10>;
					bias-pull-up;
				};
			};

			atmel_rst_suspend: atmel_rst_suspend {
				mux {
					pins = "gpio60";
					function = "gpio";
				};

				config {
					pins = "gpio60";
					drive-strength = <2>;
					bias-disable;
				};
			};
		};
		fsa8069_irq_pin:fsa8069_irq_pin {
			// qcom,pins = <&gp 95>;
			// qcom,num-grp-pins = <1>;
			// qcom,pin-func = <0>;
			// label = "fsa8069_irq_pin";

			fsa8069_irq_active: fsa8069_irq_active{
				mux {
					pins = "gpio95";
					function = "gpio";
				};

				config {
					pins = "gpio95";
					bias-pull-up;
					input-enable;
				};
			};

			fsa8069_irq_suspend: fsa8069_irq_suspend{
				mux {
					pins = "gpio95";
					function = "gpio";
				};

				config {
					pins = "gpio95";
					input-enable;
					bias-pull-up;
				};
			};
		};
	};
};
